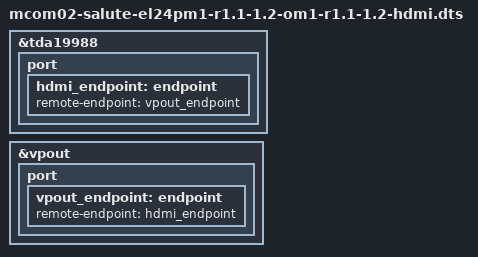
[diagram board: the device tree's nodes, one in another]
/*
 * Copyright 2017 RnD Center "ELVEES", JSC
 *
 * This program is free software; you can redistribute it and/or modify
 * it under the terms of the GNU General Public License version 2 as
 * published by the Free Software Foundation.
 */

/dts-v1/;

#include "mcom02-salute-el24pm1-r1.1-1.2-om1-r1.1-1.2.dtsi"

&tda19988 {
	status = "okay";

	port {
		hdmi_endpoint: endpoint {
			remote-endpoint = <&vpout_endpoint>;
		};
	};
};

&vpout {
	status = "okay";

	port {
		vpout_endpoint: endpoint {
			remote-endpoint = <&hdmi_endpoint>;
		};
	};
};
